# RS1xxxx register map
Vendor: Silicon Lab Inc.; Series: ARMCM4; File version: 1.2
CPU: CM4 r1p0, little endian, MPU, FPU, 6 interrupt priority bits
Registers are 32-bit, read-write, reset 0x0 unless marked. A register's access mark holds for its fields unless they carry their own. Offsets are from the block's base; [hi:lo] are bit positions; {n}, {i} and the like mark numbered series.

## UART0 — Universal Asynchronous Receiver/Transmitter is for serial communication with peripherals, modems and datasets
Base 0x44000000
Same registers: ULP_UART 0x24041800, UART1 0x45020000
0x00 DLL — Divisor Latch Low
  [7:0] DLL — Lower 8-bits of a 16-bit, read/write, Divisor Latch register that contains the baud rate divisor for the UART.
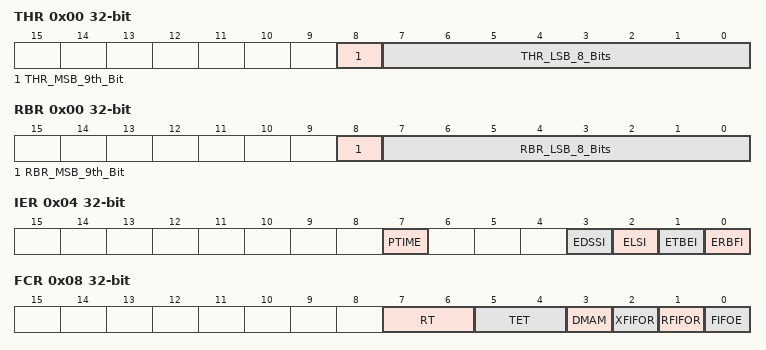
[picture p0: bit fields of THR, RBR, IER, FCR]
0x00 THR wo (reset mask 0xFF) (alternate view of DLL) — Transmit Holding Register
  [8] THR_MSB_9th_Bit — Data to be transmitted on the serial output port(sout) in UART mode for the MSB 9th bit.
  [7:0] THR_LSB_8_Bits — Data to be transmitted on serial output port
0x00 RBR ro (reset mask 0xFF) (alternate view of DLL) — Receive Buffer Register
  [8] RBR_MSB_9th_Bit — Data byte received on the serial input port (sin) in UART mode for the MSB 9th bit.
  [7:0] RBR_LSB_8_Bits — Receive Buffer Field
0x00 DLH (alternate view of DLL) — Divisor Latch High
  [7:0] DLH — Upper 8-bits of a 16-bit, read/write, Divisor Latch register that contains the baud rate divisor for the UART
0x04 IER — Interrupt Enable Register
  [7] PTIME — Programmable THRE Interrupt Mode Enable
    0=Disable (generation of THRE Interrupt is disabled); 1=Enable (generation of THRE Interrupt is enabled)
  [3] EDSSI — Enable Modem Status Interrupt
    0=Disable (Modem Status Interrupt is disabled); 1=Enable (Modem Status Interrupt is enabled)
  [2] ELSI — Enable Receiver Line Status Interrupt
    0=Disable (Receiver Line Status Interrupt is disabled); 1=Enable (Receiver Line Status Interrupt is enabled)
  [1] ETBEI — Enable Transmit Holding Register Empty Interrupt
    0=Disable (Transmit Holding Register Empty Interrupt is disabled); 1=Enable (Transmit Holding Register Empty Interrupt is enabled)
  [0] ERBFI — Enable Received Data Available Interrupt
    0=Disable (Received Data Available Interrupt is disabled); 1=Enable (Received Data Available Interrupt is enabled)
0x08 FCR wo — FIFO Control Register
  [7:6] RT — This is used to select the trigger level in the receiver FIFO at which the Received Data Available Interrupt is generated
    on write: 0=FIFO_1_CHARACTER (1 character in the FIFO); 1=FIFO_1_BY_4_CHARACTER (FIFO 1/4 full); 2=FIFO_1_BY_2_CHARACTER (FIFO 1/2 full); 3=FIFO_LESS_THAN_2_CHARACTER (FIFO 2 less than full)
  [5:4] TET — TX Empty Trigger
    on write: 0=FIFO_EMPTY; 1=FIFO_2_CHARACTER (2 characters in the FIFO); 2=FIFO_1_BY_4_CHARACTER (FIFO 1/4 full); 3=FIFO_1_BY_2_CHARACTER (FIFO 1/2 full)
  [3] DMAM — DMA signalling mode
    0=Mode0 (DMA Signalling mode0); 1=Mode1 (DMA Signalling mode1)
  [2] XFIFOR — XMIT FIFO Reset
  [1] RFIFOR — RCVR FIFO Reset
  [0] FIFOE — This enables/disables the transmit (XMIT) and receive (RCVR) FIFOs
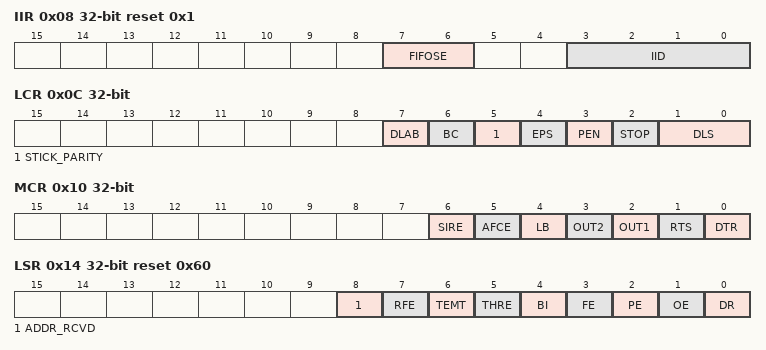
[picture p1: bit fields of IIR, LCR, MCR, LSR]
0x08 IIR ro reset 0x1 — Interrupt Identity Register
  [7:6] FIFOSE — This is used to indicate whether the FIFOs are enabled or disabled.
    on read: 0=Disable (FIFO is disabled); 3=Enable (FIFO is enabled)
  [3:0] IID — Interrupt ID
    on read: 0=modem status pending pending interrupt; 1=No_Interrupt_Pending (This field indicates no interrupt pending status); 2=THR_Empty (Transmit Holding Register Empty pending interrupt); 4=Receive_Data_Available (Received Data Available pending interrupt); 6=Receiver_Line_Status (Receive line status pending interrupt); 7=Busy detect pending interrupt; 12=Character Timeout pending interrupt
0x0C LCR — Line Control Register
  [7] DLAB — enable reading and writing of the Divisor Latch register, This bit must be cleared after initial baud rate set up
  [6] BC — This is used to cause a break condition to be transmitted to the receiving device
    1=SERIAL_OUTPUT_SPACING_STATE (If set to 1, the serial output is forced to the spacing (logic 0) state)
  [5] STICK_PARITY — This bit is used to force parity value
    0=LOGIC0 (When PEN, EPS, and Stick Parity are set to 1, the parity bit is transmitted and checked as logic 0); 1=LOGIC1 (If PEN and Stick Parity are set to 1 and EPS is a logic 0,then parity bit is transmitted and checked as a logic 1)
  [4] EPS — This is used to select between even and odd parity
    0=Set_to_0 (An odd number of logic 1s is transmitted or checked); 1=Set_to_1 (An even number of logic 1s is transmitted or checked)
  [3] PEN — This bit is used to enable and disable parity generation and detection in transmitted and received serial character
    0=Parity disabled; 1=Parity Enabled
  [2] STOP — This is used to select the number of stop bits per character that the peripheral transmits and receives
    0=1_STOP_BIT_PER_CHARACTER; 1=1_5_OR_2_STOPS_BIT_PER_CHARACTER (1.5 or 2 stop bits per character)
  [1:0] DLS — Data Length Select,This is used to select the number of data bits per character that the peripheral transmits and receives
    {v}={v+5}_BITS_PER_CHARACTER (v=0..3)
0x10 MCR — Modem Control Register
  [6] SIRE — This is used to enable/disable the IrDA SIR Mode features
    0=Disabled (IrDA SIR Mode disabled); 1=Enabled (IrDA SIR Mode enabled)
  [5] AFCE — This is used to directly control the user-designated Output2 (out2_n) output
    0=Disabled (Auto Flow Control Mode disabled); 1=Enabled (Auto Flow Control Mode enabled)
  [4] LB — This is used to put the UART into a diagnostic mode for test purposes
  [3] OUT2 — This is used to directly control the user-designated Output2 (out2_n) output
    0=OUT2_LOGIC1 (out2_n de-asserted (logic 1)); 1=OUT2_LOGIC0 (out2_n asserted (logic 0))
  [2] OUT1 — This is used to directly control the user-designated Output1 (out1_n) output
    0=OUT1_LOGIC1 (out1_n de-asserted (logic 1)); 1=OUT1_LOGIC0 (out1_n asserted (logic 0))
  [1] RTS — This is used to directly control the Request to Send (rts_n) output
  [0] DTR — This is used to directly control the Data Terminal Ready (dtr_n) output
    0=DTR_LOGIC1 (dtr_n de-asserted (logic 1)); 1=DTR_LOGIC0 (dtr_n asserted (logic 0))
0x14 LSR ro reset 0x60 — Line Status Register
  [8] ADDR_RCVD — Address Received bit,If 9-bit data mode (LCR_EXT[0]=1) is enabled, this bit is used to indicate that the 9th bit of the receive data is set to 1.
    on read: 1=Character_is_Address (Indicates that the character is an address.); 0=Character_is_Data (Indicates that the character is data.)
  [7] RFE — This is used to indicate if there is at least one parity error,framing error, or break indication in the FIFO
    on read: 0=No_Error_in_RX_FIFO; 1=Error_in_RX_FIFO
  [6] TEMT — Transmitter Empty bit
  [5] THRE — Transmit Holding Register Empty bit
  [4] BI — his is used to indicate the detection of a break sequence on the serial input data
  [3] FE — This is used to indicate the occurrence of a framing error in the receiver
    on read: 0=No_Framing_Error; 1=Framing_Error
  [2] PE — This is used to indicate the occurrence of a parity error in the receiver if the Parity Enable (PEN) bit (LCR[3]) is set
    on read: 0=No_Parity_Error; 1=Parity_Error
  [1] OE — This is used to indicate the occurrence of an overrun error
    on read: 0=No_OverRun_Error; 1=OverRun_Error
  [0] DR — This is used to indicate that the receiver contains at least one character in the RBR or the receiver FIFO
    on read: 0=No_Data_Ready; 1=Data_Ready
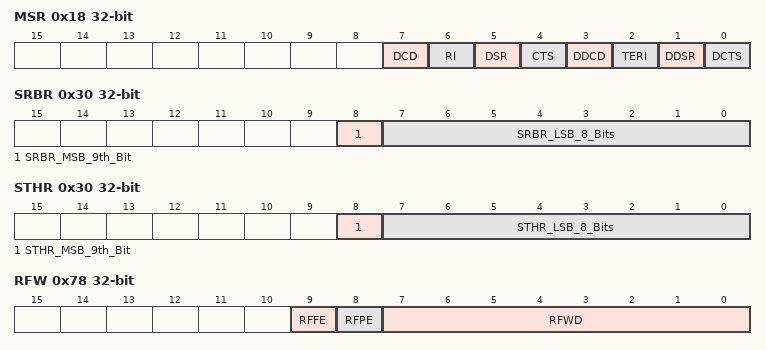
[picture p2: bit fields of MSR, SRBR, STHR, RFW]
0x18 MSR ro — Modem Status Register
  [7] DCD — This is used to indicate the current state of the modem control line dcd_n
    on read: 0=Deasserted (dcd_n input is de-asserted (logic 1)); 1=Asserted (dcd_n input is asserted (logic 0))
  [6] RI — This is used to indicate the current state of the modem control line ri_n
    on read: 0=Deasserted (ri_n input is de-asserted (logic 1)); 1=Asserted (ri_n input is asserted (logic 0))
  [5] DSR — This is used to indicate the current state of the modem control line dsr_n
    on read: 0=Deasserted (dsr_n input is de-asserted (logic 1)); 1=Asserted (dsr_n input is asserted (logic 0))
  [4] CTS — This is used to indicate the current state of the modem control line cts_n
    on read: 0=Deasserted (cts_n input is de-asserted (logic 1)); 1=Asserted (cts_n input is asserted (logic 0))
  [3] DDCD — This is used to indicate that the modem control line dcd_n has changed since the last time the MSR was read
    on read: 0=no change on dcd_n since last read of MSR; 1=change on dcd_n since last read of MSR
  [2] TERI — This is used to indicate that a change on the input ri_n(from an active-low to an inactive-high state)has occurred since the last time the MSR was read
    on read: 0=no change on ri_n since last read of MSR; 1=change on ri_n since last read of MSR
  [1] DDSR — This is used to indicate that the modem control line dsr_n has changed since the last time the MSR was read
    on read: 0=no change on dsr_n since last read of MSR; 1=change on dsr_n since last read of MSR
  [0] DCTS — This is used to indicate that the modem control line cts_n has changed since the last time the MSR was read
    on read: 0=no change on cts_n since last read of MSR; 1=change on cts_n since last read of MSR
0x1C SCR — Scratch pad Register
  [7:0] SCRATCH_PAD — This register is for programmers to use as a temporary storage space. It has no defined purpose
0x20 LPDLL — Low Power Divisor Latch Low Register
  [7:0] LPDLL — This register makes up the lower 8-bits of a 16-bit, read/write, Low Power Divisor Latch register that contains the baud rate divisor for the UART, which must give a baud rate of 115.2K
0x24 LPDLH — Low Power Divisor Latch High Register
  [7:0] LPDLH — This register makes up the upper 8-bits of a 16-bit, read/write, Low Power Divisor Latch register that contains the baud rate divisor for the UART, which must give a baud rate of 115200
0x30 SRBR ro (reset mask 0xFF) (alternate view of STHR) — Shadow Receive Buffer Register
  [8] SRBR_MSB_9th_Bit — This is a shadow register for the RBR[8] bit.It is applicable only when UART_9BIT_DATA_EN=1.
  [7:0] SRBR_LSB_8_Bits — This register contains the data byte received on the serial input port (sin) in UART mode or the serial infrared input (sir_in) in infrared mode
0x30 STHR wo (reset mask 0xFF) (alternate view of SRBR) — Transmit Holding Register
  [8] STHR_MSB_9th_Bit — This is a shadow register for the THR[8] bit.It is applicable only when UART_9BIT_DATA_EN=1
  [7:0] STHR_LSB_8_Bits — Data to be transmitted on serial output port
0x70 FAR — This register is use to enable a FIFO access mode for testing,
  [0] FIFO_Access
0x74 TFR ro — Reading this register gives the data at the top of the transmit FIFO.Each consecutive read pops the transmit FIFO and gives next data in FIFO
  [7:0] TX_FIFO_RD — Transmit FIFO Read
0x78 RFW
  [9] RFFE wo — Receive FIFO Framing Error
  [8] RFPE wo — Receive FIFO Parity Error
  [7:0] RFWD wo — Receive FIFO Write Data
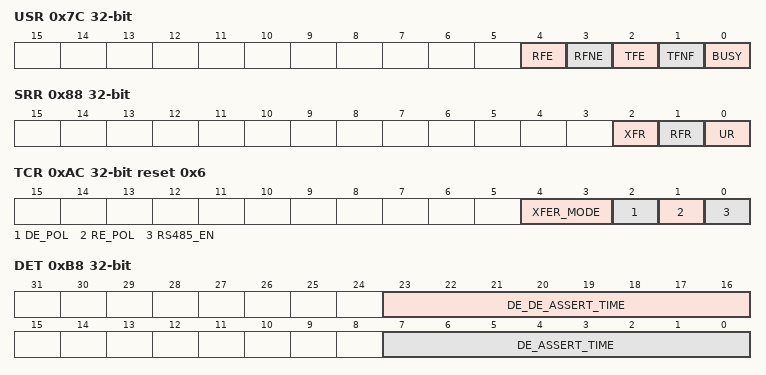
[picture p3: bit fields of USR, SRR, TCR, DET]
0x7C USR ro — UART Status Register
  [4] RFE — To Indicate that the receive FIFO is completely full
    on read: 0=Receive_FIFO_Not_Full; 1=Receive_FIFO_Full
  [3] RFNE — To Indicate that the receive FIFO contains one or more entries
    on read: 0=Receive_FIFO_Empty (Receive FIFO is empty); 1=Receive FIFO_Not_Empty (Receive FIFO is not empty)
  [2] TFE — To Indicate that the transmit FIFO is completely empty
    on read: 0=Transmit_FIFO_Empty (Transmit FIFO is not empty); 1=Transmit_FIFO_Empty (Transmit FIFO is empty)
  [1] TFNF — To Indicate that the transmit FIFO is not full
    on read: 0=Transmit_FIFO_Full (Transmit FIFO is full); 1=Transmit_FIFO_Not_Full (Transmit FIFO is not full)
  [0] BUSY — Indicates that a serial transfer is in progress
    on read: 0=UART_IDLE (UART is idle or inactive); 1=UART_BUSY (UART is busy (actively transferring data))
0x80 TFL ro — Transmit FIFO Level
  [29:0] Transmit_FIFO_Level — Transmit FIFO Level. This is indicates the number of data entries in the transmit FIFO.
0x84 RFL ro — Receive FIFO Level
  [29:0] Receive_FIFO_Level — Receive FIFO Level. This is indicates the number of data entries in the receive FIFO.
0x88 SRR — Software Reset Register
  [2] XFR wo — XMIT FIFO Reset
  [1] RFR wo — RCVR FIFO Reset
  [0] UR wo — UART Reset
0x8C SRTS — Shadow Request to Send
  [0] SRTS — Shadow Request to Send.
0x90 SBCR — Shadow Break Control Register
  [0] SBCR — Shadow Break Control Bit
0x94 SDMAM — Shadow DMA Mode
  [0] SDMAM
    0=MODE0; 1=MODE1
0x98 SFE — Shadow FIFO Enable
  [0] Shadow_FIFO_En
0x9C SRT — Shadow RCVR Trigger
  [0] SRCVRT
    0=1_Character_in_FIFO; 1=FIFO_1_4th_Full; 2=FIFO_Half_Full (FIFO 1/2 Full); 3=FIFO_2_Less_than_Full
0xA0 STET — Shadow TX Empty Trigger
  [1:0] STXET
    0=FIFO_Empty; 1=2_Characters_in_FIFO; 2=FIFO_1_4th_Full; 3=FIFO_Half_Full (FIFO 1/2 Full)
0xA4 HTX — Halt Transmit
  [0] HALT_TX — This register is use to halt transmissions for testing
    0=Disabled (Halt TX disabled); 1=Enabled (Halt TX enabled)
0xA8 DMASA — DMA Software Acknowledge
  [0] DMA_SOFTWARE_ACK wo — This register is use to perform a DMA software acknowledge if a transfer needs to be terminated due to an error condition
0xAC TCR reset 0x6 — Transceiver Control Register.
  [4:3] XFER_MODE — Transfer Mode.
  [2] DE_POL — Driver Enable Polarity.
    0=Active_Low (DE signal is active low); 1=Active_High (DE signal is active high)
  [1] RE_POL — Receiver Enable Polarity.
    0=Active_Low (RE signal is active low); 1=Active_High (RE signal is active high)
  [0] RS485_EN — RS485 Transfer Enable.
0xB0 DE_EN — Driver Output Enable Register.
  [0] DE_EN — DE Enable control.
    0=De-assert 'de' signal; 1=Assert 'de' signal
0xB4 RE_EN — Receiver Output Enable Register.
  [0] RE_EN — RE Enable control.
    0=De-assert 're' signal; 1=Assert 're' signal
0xB8 DET — Driver Output Enable Timing Register.
  [23:16] DE_DE_ASSERT_TIME — Driver enable de-assertion time.
  [7:0] DE_ASSERT_TIME — Driver enable assertion time.
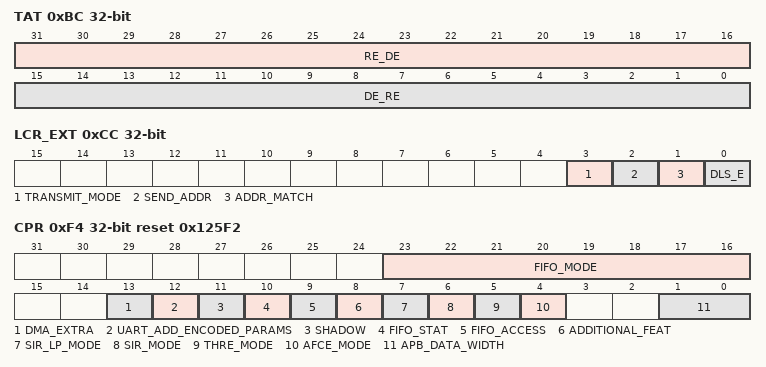
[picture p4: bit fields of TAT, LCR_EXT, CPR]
0xBC TAT — TurnAround Timing Register
  [31:16] RE_DE — Receiver Enable to Driver Enable TurnAround time.
  [15:0] DE_RE — Driver Enable to Receiver Enable TurnAround time.
0xC0 DLF — Divisor Latch Fraction Register.
  [5:0] DLF_Val — Fractional part of divisor.
0xC4 RAR — Receive Address Register.
  [7:0] RAR — This is an address matching register during receive mode.
0xC8 TAR — Transmit Address Register.
  [7:0] TAR — This is an address matching register during transmit mode.
0xCC LCR_EXT — Line Extended Control Register
  [3] TRANSMIT_MODE — Transmit mode control bit.
  [2] SEND_ADDR — Send address control bit.
  [1] ADDR_MATCH — Address Match Mode.
  [0] DLS_E — Extension for DLS.
0xF4 CPR ro reset 0x125F2 — Component Parameter Register
  [23:16] FIFO_MODE
  [13] DMA_EXTRA
    on read: 1=TRUE; 0=FALSE
  [12] UART_ADD_ENCODED_PARAMS
    on read: 1=TRUE; 0=FALSE
  [11] SHADOW
    on read: 1=TRUE; 0=FALSE
  [10] FIFO_STAT
    on read: 1=TRUE; 0=FALSE
  [9] FIFO_ACCESS
    on read: 1=TRUE; 0=FALSE
  [8] ADDITIONAL_FEAT
    on read: 1=TRUE; 0=FALSE
  [7] SIR_LP_MODE
    on read: 1=TRUE; 0=FALSE
  [6] SIR_MODE
    on read: 1=TRUE; 0=FALSE
  [5] THRE_MODE
    on read: 1=TRUE; 0=FALSE
  [4] AFCE_MODE
    on read: 1=TRUE; 0=FALSE
  [1:0] APB_DATA_WIDTH
    on read: 0=8_BIT (APB Data Width 8 BIT); 1=16_BIT (APB Data Width 16 BIT); 2=32_BIT (APB Data Width 32 BIT)
0xF8 UCV ro reset 0x3430302A — UART Component Version
  [31:0] UART_COMP_VER — This register contains UART Component Version.
0xFC CTR ro reset 0x44570110 — Component Type Register,This register contains the peripherals identification code
  [31:0] UART_COMP_VER — This register contains the peripherals identification code.

## Notices in the file
Copyright (C) 2012 ARM Limited. All rights reserved.
Purpose: System Viewer Description (SVD) Example (Schema Version 1.1)
This is a description of a none-existent and incomplete device
for demonstration purposes only.
Redistribution and use in source and binary forms, with or without
modification, are permitted provided that the following conditions are met:
- Redistributions of source code must retain the above copyright
notice, this list of conditions and the following disclaimer.
- Redistributions in binary form must reproduce the above copyright
notice, this list of conditions and the following disclaimer in the
documentation and/or other materials provided with the distribution.
- Neither the name of ARM nor the names of its contributors may be used
to endorse or promote products derived from this software without
specific prior written permission.
THIS SOFTWARE IS PROVIDED BY THE COPYRIGHT HOLDERS AND CONTRIBUTORS "AS IS"
AND ANY EXPRESS OR IMPLIED WARRANTIES, INCLUDING, BUT NOT LIMITED TO, THE
IMPLIED WARRANTIES OF MERCHANTABILITY AND FITNESS FOR A PARTICULAR PURPOSE
ARE DISCLAIMED. IN NO EVENT SHALL COPYRIGHT HOLDERS AND CONTRIBUTORS BE
LIABLE FOR ANY DIRECT, INDIRECT, INCIDENTAL, SPECIAL, EXEMPLARY, OR
CONSEQUENTIAL DAMAGES (INCLUDING, BUT NOT LIMITED TO, PROCUREMENT OF
SUBSTITUTE GOODS OR SERVICES; LOSS OF USE, DATA, OR PROFITS; OR BUSINESS
INTERRUPTION) HOWEVER CAUSED AND ON ANY THEORY OF LIABILITY, WHETHER IN
CONTRACT, STRICT LIABILITY, OR TORT (INCLUDING NEGLIGENCE OR OTHERWISE)
ARISING IN ANY WAY OUT OF THE USE OF THIS SOFTWARE, EVEN IF ADVISED OF THE
POSSIBILITY OF SUCH DAMAGE.
